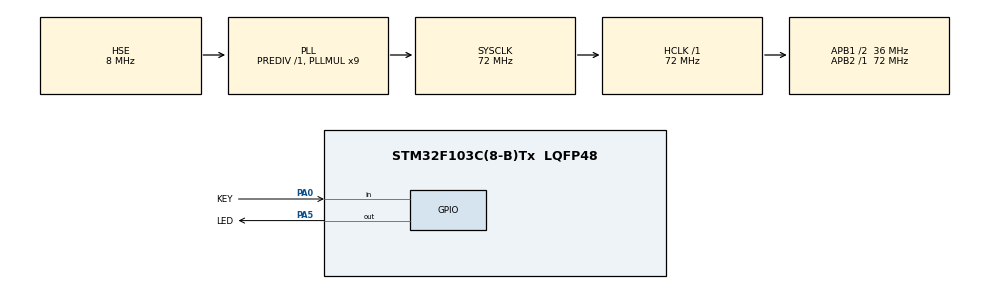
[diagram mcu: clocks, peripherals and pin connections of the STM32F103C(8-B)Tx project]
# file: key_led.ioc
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Mcu.Family=STM32F1
Mcu.Name=STM32F103C(8-B)Tx
Mcu.Package=LQFP48
NVIC.PriorityGroup=NVIC_PRIORITYGROUP_4
PA0-WKUP.GPIO_Label=KEY
PA0-WKUP.GPIO_PuPd=GPIO_PULLUP
PA0-WKUP.Signal=GPIO_Input
PA13.Mode=Serial_Wire
PA13.Signal=SYS_JTMS-SWDIO
PA14.Mode=Serial_Wire
PA14.Signal=SYS_JTCK-SWCLK
PA5.GPIO_Label=LED
PA5.GPIO_Speed=GPIO_SPEED_FREQ_HIGH
PA5.PinState=GPIO_PIN_SET
PA5.Signal=GPIO_Output
PD0-OSC_IN.Mode=HSE-External-Oscillator
PD0-OSC_IN.Signal=RCC_OSC_IN
PD1-OSC_OUT.Mode=HSE-External-Oscillator
PD1-OSC_OUT.Signal=RCC_OSC_OUT
ProjectManager.HeapSize=0x200
ProjectManager.StackSize=0x400
ProjectManager.TargetToolchain=CMake
RCC.AHBFreq_Value=72000000
RCC.APB1CLKDivider=RCC_HCLK_DIV2
RCC.APB1Freq_Value=36000000
RCC.APB1TimFreq_Value=72000000
RCC.APB2Freq_Value=72000000
RCC.APB2TimFreq_Value=72000000
RCC.HCLKFreq_Value=72000000
RCC.PLLMUL=RCC_PLL_MUL9
RCC.PLLSourceVirtual=RCC_PLLSOURCE_HSE
RCC.SYSCLKFreq_VALUE=72000000
RCC.SYSCLKSource=RCC_SYSCLKSOURCE_PLLCLK
RCC.USBFreq_Value=72000000
board=custom

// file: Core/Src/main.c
/* USER CODE BEGIN Header */
/**
  ******************************************************************************
  * @file           : main.c
  * @brief          : Main program body
  ******************************************************************************
  * @attention
  *
  * Copyright (c) 2025 STMicroelectronics.
  * All rights reserved.
  *
  * This software is licensed under terms that can be found in the LICENSE file
  * in the root directory of this software component.
  * If no LICENSE file comes with this software, it is provided AS-IS.
  *
  ******************************************************************************
  */
/* USER CODE END Header */
#include "main.h"
#include "gpio.h"
#include "stm32f1xx_hal_gpio.h"
#include <stdint.h>

/* USER CODE BEGIN PD */

// 定义按键和LED的引脚
#define KEY_PIN GPIO_PIN_0
#define KEY_GPIO_PORT GPIOA
#define LED_PIN GPIO_PIN_5
#define LED_GPIO_PORT GPIOA

// 定义按键状态
#define KEY_PRESSED 0 // 按键按下时为低电平
#define KEY_RELEASED 1  // 按键释放时为高电平

/* USER CODE END PD */

/* USER CODE BEGIN PV */

uint8_t key_state = KEY_RELEASED; // 当前按键状态
uint8_t key_last_state = KEY_RELEASED; // 上一个按键状态
uint8_t led_state = 0; // LED状态，0表示关闭，1表示打开
uint32_t debounce_delay = 50; // 消抖时间
uint32_t last_debounce_time = 0; // 上次消抖时间

/* USER CODE END PV */

void SystemClock_Config(void);
/* USER CODE BEGIN PFP */

uint8_t KEY_Scan(void);
void LED_Toggle(void);

/* USER CODE END PFP */

/* USER CODE BEGIN 0 */

// 按键扫描函数，带消抖处理
uint8_t KEY_Scan(void) {
  uint8_t current_state = HAL_GPIO_ReadPin(KEY_GPIO_PORT, KEY_PIN);

  // 检测按键状态变化
  if (current_state != key_last_state) {
    last_debounce_time = HAL_GetTick(); // 记录状态变化时间
  }

  // 如果状态稳定超过消抖时间，则更新按键状态
  if ((HAL_GetTick() - last_debounce_time) > debounce_delay) {
    if (current_state != key_state) {
      key_state = current_state;
    }
  }

  key_last_state = current_state;
  return key_state;
}

// 翻转LED状态函数
void LED_Toggle(void) {
  led_state = !led_state; // 切换LED状态
  HAL_GPIO_WritePin(LED_GPIO_PORT, LED_PIN, led_state ? GPIO_PIN_SET : GPIO_PIN_RESET);
}

/* USER CODE END 0 */

int main(void)
{

  /* MCU Configuration--------------------------------------------------------*/

  /* Reset of all peripherals, Initializes the Flash interface and the Systick. */
  HAL_Init();

  /* Configure the system clock */
  SystemClock_Config();

  /* Initialize all configured peripherals */
  MX_GPIO_Init();
  /* USER CODE BEGIN 2 */

  // 初始化LED状态为关闭
  HAL_GPIO_WritePin(LED_GPIO_PORT, LED_PIN, GPIO_PIN_RESET);
  led_state = 0;  // 确保led_state变量与实际状态一致

  /* USER CODE END 2 */

  /* Infinite loop */
  while (1)
  {

    /* USER CODE BEGIN 3 */

    // 检测按键是否按下
    if (KEY_Scan() == KEY_PRESSED) {
      // 按键按下，翻转LED状态
      LED_Toggle();

      // 等待按键释放，防止多次触发
      while (KEY_Scan() == KEY_PRESSED) {
        HAL_Delay(10); // 小延时，避免占用过多CPU资源
      }
    }

    // 小延时，避免占用过多CPU资源
    HAL_Delay(10);
  }
  /* USER CODE END 3 */
}

void SystemClock_Config(void)
{
  RCC_OscInitTypeDef RCC_OscInitStruct = {0};
  RCC_ClkInitTypeDef RCC_ClkInitStruct = {0};

  /** Initializes the RCC Oscillators according to the specified parameters
  * in the RCC_OscInitTypeDef structure.
  */
  RCC_OscInitStruct.OscillatorType = RCC_OSCILLATORTYPE_HSE;
  RCC_OscInitStruct.HSEState = RCC_HSE_ON;
  RCC_OscInitStruct.HSEPredivValue = RCC_HSE_PREDIV_DIV1;
  RCC_OscInitStruct.HSIState = RCC_HSI_ON;
  RCC_OscInitStruct.PLL.PLLState = RCC_PLL_ON;
  RCC_OscInitStruct.PLL.PLLSource = RCC_PLLSOURCE_HSE;
  RCC_OscInitStruct.PLL.PLLMUL = RCC_PLL_MUL9;
  if (HAL_RCC_OscConfig(&RCC_OscInitStruct) != HAL_OK)
  {
    Error_Handler();
  }

  /** Initializes the CPU, AHB and APB buses clocks
  */
  RCC_ClkInitStruct.ClockType = RCC_CLOCKTYPE_HCLK|RCC_CLOCKTYPE_SYSCLK
                              |RCC_CLOCKTYPE_PCLK1|RCC_CLOCKTYPE_PCLK2;
  RCC_ClkInitStruct.SYSCLKSource = RCC_SYSCLKSOURCE_PLLCLK;
  RCC_ClkInitStruct.AHBCLKDivider = RCC_SYSCLK_DIV1;
  RCC_ClkInitStruct.APB1CLKDivider = RCC_HCLK_DIV2;
  RCC_ClkInitStruct.APB2CLKDivider = RCC_HCLK_DIV1;

  if (HAL_RCC_ClockConfig(&RCC_ClkInitStruct, FLASH_LATENCY_2) != HAL_OK)
  {
    Error_Handler();
  }
}

void Error_Handler(void)
{
  /* USER CODE BEGIN Error_Handler_Debug */
  /* User can add his own implementation to report the HAL error return state */
  __disable_irq();
  while (1)
  {
    // 错误状态可用闪烁LED指示
    HAL_GPIO_TogglePin(LED_GPIO_PORT, LED_PIN);
    HAL_Delay(500);
  }
  /* USER CODE END Error_Handler_Debug */
}
